# GD32E50x_HD register map
File version: 1.0
CPU: CM33 r2p1, little endian, MPU, FPU, 4 interrupt priority bits
Registers are 32-bit, read-write, reset 0x0 unless marked. A register's access mark holds for its fields unless they carry their own. Offsets are from the block's base; [hi:lo] are bit positions; {n}, {i} and the like mark numbered series.

## AFIO — Alternate-function I/Os
Base 0x40010000
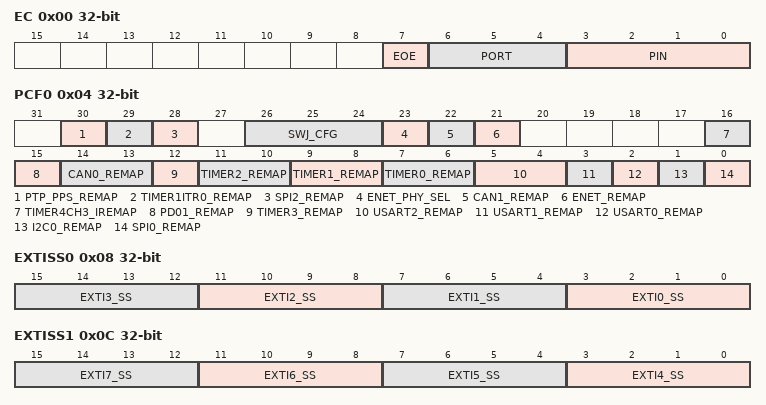
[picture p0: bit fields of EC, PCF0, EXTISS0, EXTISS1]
0x00 EC — Event control register
  [7] EOE — Event output enable
  [6:4] PORT — Event output port selection
  [3:0] PIN — Event output pin selection
0x04 PCF0 — AFIO port configuration register 0
  [30] PTP_PPS_REMAP — Ethernet PTP PPS remapping
  [29] TIMER1ITR0_REMAP — TIMER1 internal trigger 0 remapping
  [28] SPI2_REMAP — SPI2/I2S2 remapping
  [26:24] SWJ_CFG — Serial wire JTAG configuration
  [23] ENET_PHY_SEL — Ethernet MII or RMII PHY selection
  [22] CAN1_REMAP — CAN1 I/O remapping
  [21] ENET_REMAP — Ethernet MAC I/O remapping
  [16] TIMER4CH3_IREMAP — TIMER4 channel3 internal remapping
  [15] PD01_REMAP — Port D0/Port D1 mapping on OSC_IN/OSC_OUT
  [14:13] CAN0_REMAP — CAN0 alternate interface remapping
  [12] TIMER3_REMAP — TIMER3 remapping
  [11:10] TIMER2_REMAP — TIMER2 remapping
  [9:8] TIMER1_REMAP — TIMER1 remapping
  [7:6] TIMER0_REMAP — TIMER0 remapping
  [5:4] USART2_REMAP — USART2 remapping
  [3] USART1_REMAP — USART1 remapping
  [2] USART0_REMAP — USART0 remapping
  [1] I2C0_REMAP — I2C0 remapping
  [0] SPI0_REMAP — SPI0 remapping
0x08 EXTISS0 — EXTI sources selection register 0
  [4n+3:4n] EXTI{n}_SS (n=0..3) — EXTI {n} sources selection
0x0C EXTISS1 — EXTI sources selection register 1
  [4n-13:4n-16] EXTI{n}_SS (n=4..7) — EXTI {n} sources selection
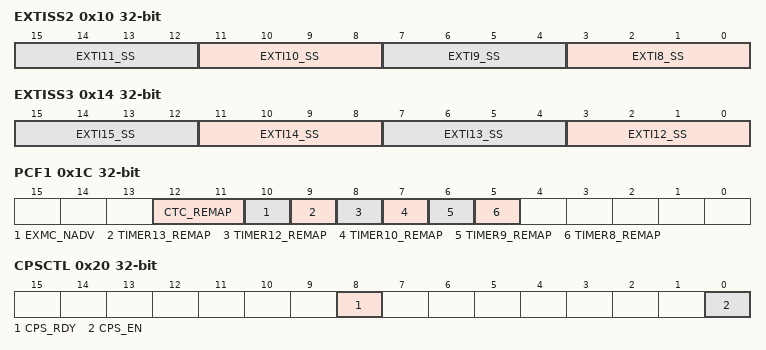
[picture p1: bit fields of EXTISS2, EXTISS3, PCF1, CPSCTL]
0x10 EXTISS2 — EXTI sources selection register 2
  [4n-29:4n-32] EXTI{n}_SS (n=8..11) — EXTI {n} sources selection
0x14 EXTISS3 — EXTI sources selection register 3
  [4n-45:4n-48] EXTI{n}_SS (n=12..15) — EXTI {n} sources selection
0x1C PCF1 — AFIO port configuration register 1
  [12:11] CTC_REMAP — CTC remapping
  [10] EXMC_NADV — EXMC_NADV connect/disconnect
  [9] TIMER13_REMAP — TIMER13 remapping
  [8] TIMER12_REMAP — TIMER12 remapping
  [7] TIMER10_REMAP — TIMER10 remapping
  [6] TIMER9_REMAP — TIMER9 remapping
  [5] TIMER8_REMAP — TIMER8 remapping
0x20 CPSCTL access per field — IO compensation control register
  [8] CPS_RDY ro — I/O compensation cell is really or not
  [0] CPS_EN rw — I/O compensation cell enable
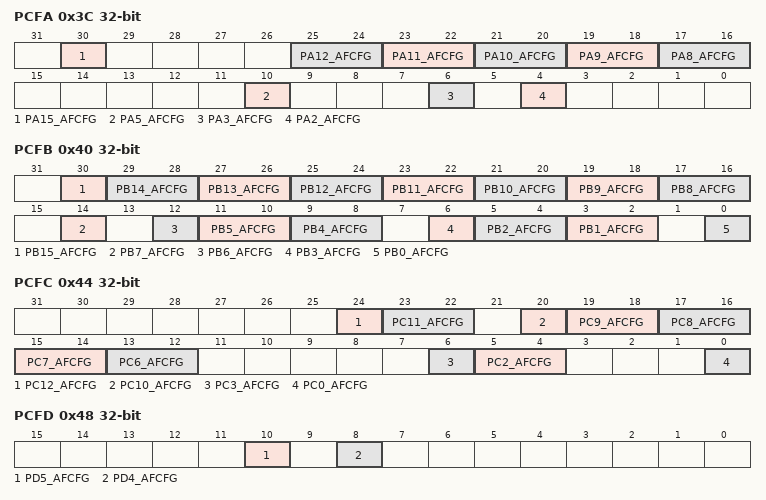
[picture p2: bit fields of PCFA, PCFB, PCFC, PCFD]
0x3C PCFA — AFIO port configuration register A
  [30] PA15_AFCFG — PA15 AF function configuration bit
  [2n+1:2n] PA{n}_AFCFG (n=8..12) — PA{n} AF function configuration bitse
  [10] PA5_AFCFG — PA5 AF function configuration bitse
  [6] PA3_AFCFG — PA3 AF function configuration bitse
  [4] PA2_AFCFG — PA2 AF function configuration bitse
0x40 PCFB — AFIO port configuration register B
  [30] PB15_AFCFG — PB15 AF function configuration bit
  [29:28] PB14_AFCFG — PB14 AF function configuration bit
  [27:26] PB13_AFCFG — PB13 AF function configuration bit
  [2n+1:2n] PB{n}_AFCFG (n=8..12) — PB{n} AF function configuration bitse
  [14] PB7_AFCFG — PB7 AF function configuration bitse
  [12] PB6_AFCFG — PB6 AF function configuration bitse
  [11:10] PB5_AFCFG — PB5 AF function configuration bitse
  [9:8] PB4_AFCFG — PB4 AF function configuration bitse
  [6] PB3_AFCFG — PB3 AF function configuration bitse
  [5:4] PB2_AFCFG — PB2 AF function configuration bitse
  [3:2] PB1_AFCFG — PB1 AF function configuration bitse
  [0] PB0_AFCFG — PB0 AF function configuration bitse
0x44 PCFC — AFIO port configuration register C
  [24] PC12_AFCFG — PC12 AF function configuration bitse
  [23:22] PC11_AFCFG — PC11 AF function configuration bitse
  [20] PC10_AFCFG — PC10 AF function configuration bitse
  [2n+1:2n] PC{n}_AFCFG (n=6..9) — PC{n} AF function configuration bitse
  [6] PC3_AFCFG — PC3 AF function configuration bitse
  [5:4] PC2_AFCFG — PC2 AF function configuration bitse
  [0] PC0_AFCFG — PC0 AF function configuration bitse
0x48 PCFD — AFIO port configuration register D
  [10] PD5_AFCFG — PD5 AF function configuration bitse
  [8] PD4_AFCFG — PD4 AF function configuration bitse
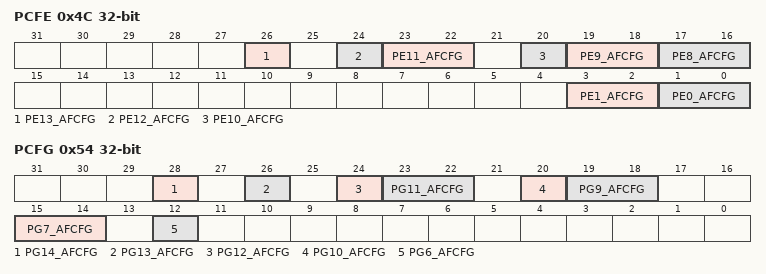
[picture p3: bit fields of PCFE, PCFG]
0x4C PCFE — AFIO port configuration register E
  [26] PE13_AFCFG — PE13 AF function configuration bitse
  [24] PE12_AFCFG — PE12 AF function configuration bitse
  [23:22] PE11_AFCFG — PE11 AF function configuration bitse
  [20] PE10_AFCFG — PE10 AF function configuration bitse
  [19:18] PE9_AFCFG — PE9 AF function configuration bitse
  [17:16] PE8_AFCFG — PE8 AF function configuration bitse
  [3:2] PE1_AFCFG — PE1 AF function configuration bitse
  [1:0] PE0_AFCFG — PE0 AF function configuration bitse
0x54 PCFG — AFIO port configuration register G
  [28] PG14_AFCFG — PG14 AF function configuration bitse
  [26] PG13_AFCFG — PG13 AF function configuration bitse
  [24] PG12_AFCFG — PG12 AF function configuration bitse
  [23:22] PG11_AFCFG — PG11 AF function configuration bitse
  [20] PG10_AFCFG — PG10 AF function configuration bitse
  [19:18] PG9_AFCFG — PG9 AF function configuration bitse
  [15:14] PG7_AFCFG — PG7 AF function configuration bitse
  [12] PG6_AFCFG — PG6 AF function configuration bitse
